# nrf9230_engb_isimcore register map
Vendor: Nordic Semiconductor; Series: nRF92; File version: 1
CPU: CM0 r0p1, little endian, MPU, no FPU, 2 interrupt priority bits, 32 interrupts
Registers are 32-bit, read-write, reset 0x0 unless marked. A register's access mark holds for its fields unless they carry their own. Offsets are from the block's base; [hi:lo] are bit positions; {n}, {i} and the like mark numbered series.

## CICTRL_NS — CICTRL 0
Base 0x47002000
Same registers: CICTRL_S 0x57002000
{0x100+4i} EVENTS_PSI[{i}] (i=0..15) — Description collection: Event generated from CryptoIsland Persistent State Interface PSI[n]
  [0] EVENTS_PSI — Event generated from CryptoIsland Persistent State Interface PSI[n]
    0=NotGenerated (Event not generated); 1=Generated (Event generated)
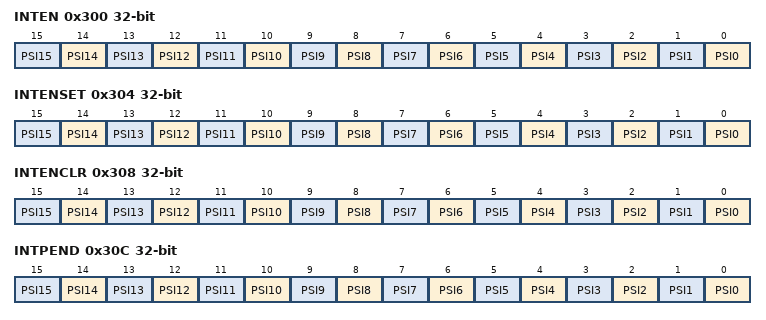
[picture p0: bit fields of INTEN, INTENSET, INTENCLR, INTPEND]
0x300 INTEN — Enable or disable interrupt
  [all] fields
    0=Disabled; 1=Enabled
  [n] PSI{n} (n=0..15) — Enable or disable interrupt for event PSI[{n}]
0x304 INTENSET — Enable interrupt
  [all] fields
    on read: 0=Disabled (Read: Disabled); 1=Enabled (Read: Enabled) | on write: 1=Set (Enable)
  [n] PSI{n} (n=0..15) — Write '1' to enable interrupt for event PSI[{n}]
0x308 INTENCLR — Disable interrupt
  [all] fields
    on read: 0=Disabled (Read: Disabled); 1=Enabled (Read: Enabled) | on write: 1=Clear (Disable)
  [n] PSI{n} (n=0..15) — Write '1' to disable interrupt for event PSI[{n}]
0x30C INTPEND ro — Pending interrupts
  [all] fields
    on read: 0=NotPending (Read: Not pending); 1=Pending (Read: Pending)
  [n] PSI{n} (n=0..15) — Read pending status of interrupt for event PSI[{n}]
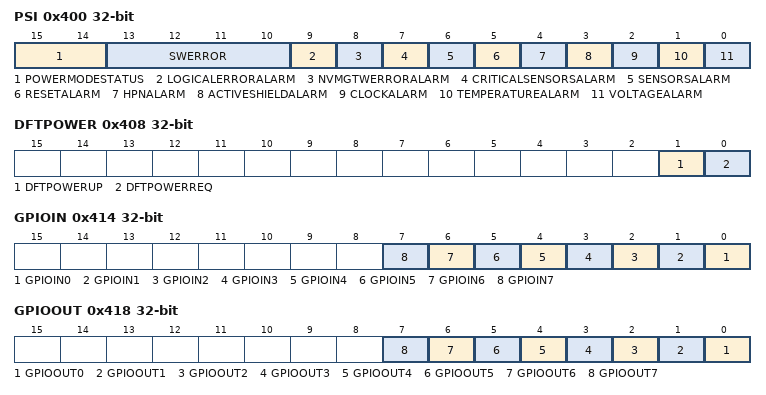
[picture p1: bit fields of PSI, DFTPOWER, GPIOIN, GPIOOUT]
0x400 PSI ro — CryptoIsland PSI status shadow register
  [15:14] POWERMODESTATUS
    0=Shutdown (In shutdown mode); 1=Retention (In retention mode); 2=Hibernate (In hibernate mode); 3=Run (Running)
  [13:10] SWERROR — SW error code
    0=NoError; 1=Attack detected by software; 2=ROM error (bad FSB); 3=OTP error 1 (bad SSB); 4=OTP error 2 (physical problem); 5=NVRError; 6=MRAM error 1 (bad runtime); 7=MRAM error 2 (bad utilities); 8=MRAM error 3 (physical problem); 9=BadProvUtility (Bad provisioning utility); 10=CommunicationError; 11=Internal error (software error); 12=Internal fault (hard fault, bus error, potential attack); 13=Bricked due to multiple attacks; 14=Permanently disabled during manufacturing; 15=Maintenance (FUT maintenance mode)
  [9] LOGICALERRORALARM — Logical error alarm: parity, duplication, shadow floops, DFA
    0=No alarm triggered; 1=Alarm triggered
  [8] NVMGTWERRORALARM — NVM unathorised access alarm
    0=No alarm triggered; 1=Alarm triggered
  [7] CRITICALSENSORSALARM — Critical sensors operation failure alarm
    0=No alarm triggered; 1=Alarm triggered
  [6] SENSORSALARM — Sensors operation failure alarm
    0=No alarm triggered; 1=Alarm triggered
  [5] RESETALARM — Reset protection alarm
    0=No warning triggered; 1=Warning triggered
  [4] HPNALARM — Honey pot network, timing and EMFI alarm
    0=No alarm triggered; 1=Alarm triggered
  [3] ACTIVESHIELDALARM
    0=No warning triggered; 1=Warning triggered
  [2] CLOCKALARM — Clock tampering alarm
    0=No alarm triggered; 1=Alarm triggered
  [1] TEMPERATUREALARM — Temperature violation alarm
    0=No alarm triggered; 1=Alarm triggered
  [0] VOLTAGEALARM — Static voltage and voltage glitch violation alarm
    0=No alarm triggered; 1=Alarm triggered
0x404 POWERMODE reset 0x3 — CryptoIsland power mode control
  [1:0] POWERMODE
    0=Shutdown (CryptoIsland to shutdown mode); 1=Hibernate (CryptoIsland to hibernate mode); 2=Retention (CryptoIsland to retention mode); 3=Run (CryptoIsland to run mode)
0x408 DFTPOWER — CryptoIsland DFT power control
  [1] DFTPOWERUP — CryptoIsland DFT power up acknowledge
    0=OFF (Power up ack off); 1=ON (Power up ack on)
  [0] DFTPOWERREQ — CryptoIsland DFT power request
    0=OFF (Power request off); 1=ON (Power request on)
0x40C DFTRESET — CryptoIsland DFT reset control. DFTRESET applies to the needs of the iSIM core DFT mode and it can also be used as a normal mode reset to reset all non-hibernate logic of CryptoIsland. DFTRESET toggles SYSRSTn input of CryptoIsland.
  [0] DFTRESETREQ — CryptoIsland DFT reset request
    0=OFF (Reset request off); 1=ON (Reset request on)
0x410 FULLRESET — CryptoIsland full reset control. FULLRESET toggles SYSRSTn and HIB_SYSRSTn inputs of CryptoIsland and can be used to reset all logic of CryptoIsland.
  [0] FULLRESETREQ — CryptoIsland full reset request
    0=OFF (Reset request off); 1=ON (Reset request on)
0x414 GPIOIN — CryptoIsland GPIO input
  [all] fields
    0=Low (Drive GPIOIN low); 1=High (Drive GPIOIN high)
  [n] GPIOIN{n} (n=0..7) — CryptoIsland GPIOIN[{n}]
0x418 GPIOOUT ro — CryptoIsland GPIO output
  [all] fields
    0=Low (GPIOOUT is low); 1=High (GPIOOUT is high)
  [n] GPIOOUT{n} (n=0..7) — CryptoIsland GPIOOUT[{n}]
0x41C POSTEDWRITEENABLE — Control register for enabling CryptoIsland initiated posted writes to system memories. Changes allowed only when CryptoIsland is not active/running.
  [0] POSTEDWRITEENABLE — CryptoIsland posted write enable
    0=Disabled (Posted writes disabled); 1=Enabled (Posted writes enabled)

## Notices in the file
Copyright (c) 2010 - 2024, Nordic Semiconductor ASA
All rights reserved.
Redistribution and use in source and binary forms, with or without modification,
are permitted provided that the following conditions are met:
1. Redistributions of source code must retain the above copyright notice, this
list of conditions and the following disclaimer.
2. Redistributions in binary form, except as embedded into a Nordic
Semiconductor ASA integrated circuit in a product or a software update for
such product, must reproduce the above copyright notice, this list of
conditions and the following disclaimer in the documentation and/or other
materials provided with the distribution.
3. Neither the name of Nordic Semiconductor ASA nor the names of its
contributors may be used to endorse or promote products derived from this
software without specific prior written permission.
4. This software, with or without modification, must only be used with a
Nordic Semiconductor ASA integrated circuit.
5. Any software provided in binary form under this license must not be reverse
engineered, decompiled, modified and/or disassembled.
THIS SOFTWARE IS PROVIDED BY NORDIC SEMICONDUCTOR ASA "AS IS" AND ANY EXPRESS
OR IMPLIED WARRANTIES, INCLUDING, BUT NOT LIMITED TO, THE IMPLIED WARRANTIES
OF MERCHANTABILITY, NONINFRINGEMENT, AND FITNESS FOR A PARTICULAR PURPOSE ARE
DISCLAIMED. IN NO EVENT SHALL NORDIC SEMICONDUCTOR ASA OR CONTRIBUTORS BE
LIABLE FOR ANY DIRECT, INDIRECT, INCIDENTAL, SPECIAL, EXEMPLARY, OR
CONSEQUENTIAL DAMAGES (INCLUDING, BUT NOT LIMITED TO, PROCUREMENT OF SUBSTITUTE
GOODS OR SERVICES; LOSS OF USE, DATA, OR PROFITS; OR BUSINESS INTERRUPTION)
HOWEVER CAUSED AND ON ANY THEORY OF LIABILITY, WHETHER IN CONTRACT, STRICT
LIABILITY, OR TORT (INCLUDING NEGLIGENCE OR OTHERWISE) ARISING IN ANY WAY OUT
OF THE USE OF THIS SOFTWARE, EVEN IF ADVISED OF THE POSSIBILITY OF SUCH DAMAGE.
